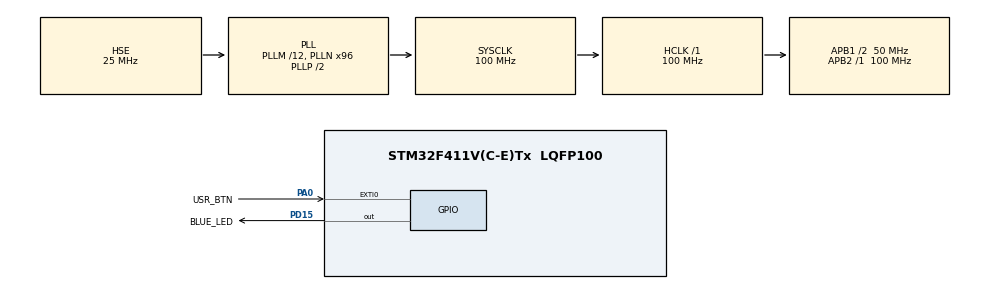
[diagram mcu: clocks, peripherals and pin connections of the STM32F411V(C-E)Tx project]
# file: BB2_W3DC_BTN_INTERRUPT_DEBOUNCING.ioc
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Mcu.Family=STM32F4
RCC.PLLSourceVirtual=RCC_PLLSOURCE_HSE
RCC.CortexFreq_Value=100000000
PD15.GPIO_Label=BLUE_LED
PH1\ -\ OSC_OUT.Mode=HSE-External-Oscillator
RCC.APB1CLKDivider=RCC_HCLK_DIV2
RCC.SYSCLKSource=RCC_SYSCLKSOURCE_PLLCLK
ProjectManager.StackSize=0x400
PA0-WKUP.GPIO_Label=USR_BTN
PA0-WKUP.Signal=GPXTI0
PA13.Signal=SYS_JTMS-SWDIO
PH0\ -\ OSC_IN.Mode=HSE-External-Oscillator
TIM1.Prescaler=32000
PH0\ -\ OSC_IN.Signal=RCC_OSC_IN
ProjectManager.TargetToolchain=STM32CubeIDE
RCC.HCLKFreq_Value=100000000
RCC.APB2TimFreq_Value=100000000
RCC.AHBFreq_Value=100000000
NVIC.TIM1_TRG_COM_TIM11_IRQn=true\:0\:0\:false\:false\:true\:true\:true
RCC.HSE_VALUE=25000000
PH1\ -\ OSC_OUT.Signal=RCC_OSC_OUT
board=custom
RCC.VCOOutputFreq_Value=200000000
RCC.APB2Freq_Value=100000000
PA14.Mode=Serial_Wire
PA13.Mode=Serial_Wire
Mcu.Name=STM32F411V(C-E)Tx
VP_TIM1_VS_ClockSourceINT.Mode=Internal
NVIC.TIM1_BRK_TIM9_IRQn=true\:0\:0\:false\:false\:true\:true\:true
NVIC.TIM1_CC_IRQn=true\:0\:0\:false\:false\:true\:true\:true
RCC.48MHZClocksFreq_Value=50000000
NVIC.EXTI0_IRQn=true\:0\:0\:false\:false\:true\:true\:true
RCC.SYSCLKFreq_VALUE=100000000
Mcu.Package=LQFP100
PA14.Signal=SYS_JTCK-SWCLK
ProjectManager.HeapSize=0x200
NVIC.TIM1_UP_TIM10_IRQn=true\:0\:0\:false\:false\:true\:true\:true
RCC.HSI_VALUE=16000000
NVIC.PriorityGroup=NVIC_PRIORITYGROUP_4
RCC.PLLM=12
RCC.PLLN=96
RCC.APB1TimFreq_Value=100000000
TIM1.Period=50
RCC.APB1Freq_Value=50000000
PD15.Signal=GPIO_Output

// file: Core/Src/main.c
/* USER CODE BEGIN Header */
/**
  ******************************************************************************
  * @file           : main.c
  * @brief          : Main program body
  ******************************************************************************
  * @attention
  *
  * <h2><center>&copy; Copyright (c) 2021 STMicroelectronics.
  * All rights reserved.</center></h2>
  *
  * This software component is licensed by ST under BSD 3-Clause license,
  * the "License"; You may not use this file except in compliance with the
  * License. You may obtain a copy of the License at:
  *                        opensource.org/licenses/BSD-3-Clause
  *
  ******************************************************************************
  */
/* USER CODE END Header */
#include "main.h"

/* USER CODE BEGIN Includes */
#include <stdbool.h>
/* USER CODE END Includes */

TIM_HandleTypeDef htim1;

/* USER CODE BEGIN PV */
bool state = true;
/* USER CODE END PV */

void SystemClock_Config(void);
static void MX_GPIO_Init(void);
static void MX_TIM1_Init(void);
/* USER CODE BEGIN PFP */
void HAL_GPIO_EXTI_Callback(uint16_t);

/* USER CODE END PFP */

int main(void)
{

  /* MCU Configuration--------------------------------------------------------*/

  /* Reset of all peripherals, Initializes the Flash interface and the Systick. */
  HAL_Init();

  /* Configure the system clock */
  SystemClock_Config();

  /* Initialize all configured peripherals */
  MX_GPIO_Init();
  MX_TIM1_Init();

  /* Infinite loop */
  while (1)
  {

  }
}

void SystemClock_Config(void)
{
  RCC_OscInitTypeDef RCC_OscInitStruct = {0};
  RCC_ClkInitTypeDef RCC_ClkInitStruct = {0};

  /** Configure the main internal regulator output voltage
  */
  __HAL_RCC_PWR_CLK_ENABLE();
  __HAL_PWR_VOLTAGESCALING_CONFIG(PWR_REGULATOR_VOLTAGE_SCALE1);
  /** Initializes the RCC Oscillators according to the specified parameters
  * in the RCC_OscInitTypeDef structure.
  */
  RCC_OscInitStruct.OscillatorType = RCC_OSCILLATORTYPE_HSE;
  RCC_OscInitStruct.HSEState = RCC_HSE_ON;
  RCC_OscInitStruct.PLL.PLLState = RCC_PLL_ON;
  RCC_OscInitStruct.PLL.PLLSource = RCC_PLLSOURCE_HSE;
  RCC_OscInitStruct.PLL.PLLM = 12;
  RCC_OscInitStruct.PLL.PLLN = 96;
  RCC_OscInitStruct.PLL.PLLP = RCC_PLLP_DIV2;
  RCC_OscInitStruct.PLL.PLLQ = 4;
  if (HAL_RCC_OscConfig(&RCC_OscInitStruct) != HAL_OK)
  {
    Error_Handler();
  }
  /** Initializes the CPU, AHB and APB buses clocks
  */
  RCC_ClkInitStruct.ClockType = RCC_CLOCKTYPE_HCLK|RCC_CLOCKTYPE_SYSCLK
                              |RCC_CLOCKTYPE_PCLK1|RCC_CLOCKTYPE_PCLK2;
  RCC_ClkInitStruct.SYSCLKSource = RCC_SYSCLKSOURCE_PLLCLK;
  RCC_ClkInitStruct.AHBCLKDivider = RCC_SYSCLK_DIV1;
  RCC_ClkInitStruct.APB1CLKDivider = RCC_HCLK_DIV2;
  RCC_ClkInitStruct.APB2CLKDivider = RCC_HCLK_DIV1;

  if (HAL_RCC_ClockConfig(&RCC_ClkInitStruct, FLASH_LATENCY_3) != HAL_OK)
  {
    Error_Handler();
  }
}

static void MX_TIM1_Init(void)
{

  TIM_ClockConfigTypeDef sClockSourceConfig = {0};
  TIM_MasterConfigTypeDef sMasterConfig = {0};

  htim1.Instance = TIM1;
  htim1.Init.Prescaler = 32000;
  htim1.Init.CounterMode = TIM_COUNTERMODE_UP;
  htim1.Init.Period = 50;
  htim1.Init.ClockDivision = TIM_CLOCKDIVISION_DIV1;
  htim1.Init.RepetitionCounter = 0;
  htim1.Init.AutoReloadPreload = TIM_AUTORELOAD_PRELOAD_DISABLE;
  if (HAL_TIM_Base_Init(&htim1) != HAL_OK)
  {
    Error_Handler();
  }
  sClockSourceConfig.ClockSource = TIM_CLOCKSOURCE_INTERNAL;
  if (HAL_TIM_ConfigClockSource(&htim1, &sClockSourceConfig) != HAL_OK)
  {
    Error_Handler();
  }
  sMasterConfig.MasterOutputTrigger = TIM_TRGO_RESET;
  sMasterConfig.MasterSlaveMode = TIM_MASTERSLAVEMODE_DISABLE;
  if (HAL_TIMEx_MasterConfigSynchronization(&htim1, &sMasterConfig) != HAL_OK)
  {
    Error_Handler();
  }

}

static void MX_GPIO_Init(void)
{
  GPIO_InitTypeDef GPIO_InitStruct = {0};

  /* GPIO Ports Clock Enable */
  __HAL_RCC_GPIOH_CLK_ENABLE();
  __HAL_RCC_GPIOA_CLK_ENABLE();
  __HAL_RCC_GPIOD_CLK_ENABLE();

  /*Configure GPIO pin Output Level */
  HAL_GPIO_WritePin(BLUE_LED_GPIO_Port, BLUE_LED_Pin, GPIO_PIN_RESET);

  /*Configure GPIO pin : USR_BTN_Pin */
  GPIO_InitStruct.Pin = USR_BTN_Pin;
  GPIO_InitStruct.Mode = GPIO_MODE_IT_RISING;
  GPIO_InitStruct.Pull = GPIO_NOPULL;
  HAL_GPIO_Init(USR_BTN_GPIO_Port, &GPIO_InitStruct);

  /*Configure GPIO pin : BLUE_LED_Pin */
  GPIO_InitStruct.Pin = BLUE_LED_Pin;
  GPIO_InitStruct.Mode = GPIO_MODE_OUTPUT_PP;
  GPIO_InitStruct.Pull = GPIO_NOPULL;
  GPIO_InitStruct.Speed = GPIO_SPEED_FREQ_LOW;
  HAL_GPIO_Init(BLUE_LED_GPIO_Port, &GPIO_InitStruct);

  /* EXTI interrupt init*/
  HAL_NVIC_SetPriority(EXTI0_IRQn, 0, 0);
  HAL_NVIC_EnableIRQ(EXTI0_IRQn);

}

/* USER CODE BEGIN 4 */
void HAL_GPIO_EXTI_Callback(uint16_t GPIO_Pin)
{
	  //if (GPIO_Pin == USER_BTN_Pin)
		//  HAL_GPIO_TogglePin(LED1_GPIO_Port, LED1_Pin);

		if(GPIO_Pin == USR_BTN_Pin && state == true){
			HAL_TIM_Base_Start_IT(&htim1);
			state = false;
		}
		else{
			__NOP();
		}
}

void HAL_TIM_PeriodElapsedCallback(TIM_HandleTypeDef *htim)
{
  /* Prevent unused argument(s) compilation warning */
  UNUSED(htim);

  /* NOTE : This function should not be modified, when the callback is needed,
            the HAL_TIM_PeriodElapsedCallback could be implemented in the user file
   */
	if(HAL_GPIO_ReadPin(USR_BTN_GPIO_Port, USR_BTN_Pin) == GPIO_PIN_RESET){
		HAL_GPIO_TogglePin(BLUE_LED_GPIO_Port, BLUE_LED_Pin);
		state = true;
		HAL_TIM_Base_Stop_IT(&htim1);
	}
}
/* USER CODE END 4 */

void Error_Handler(void)
{
  __disable_irq();
  while (1)
  {
  }
}

/************************ (C) COPYRIGHT STMicroelectronics *****END OF FILE****/
